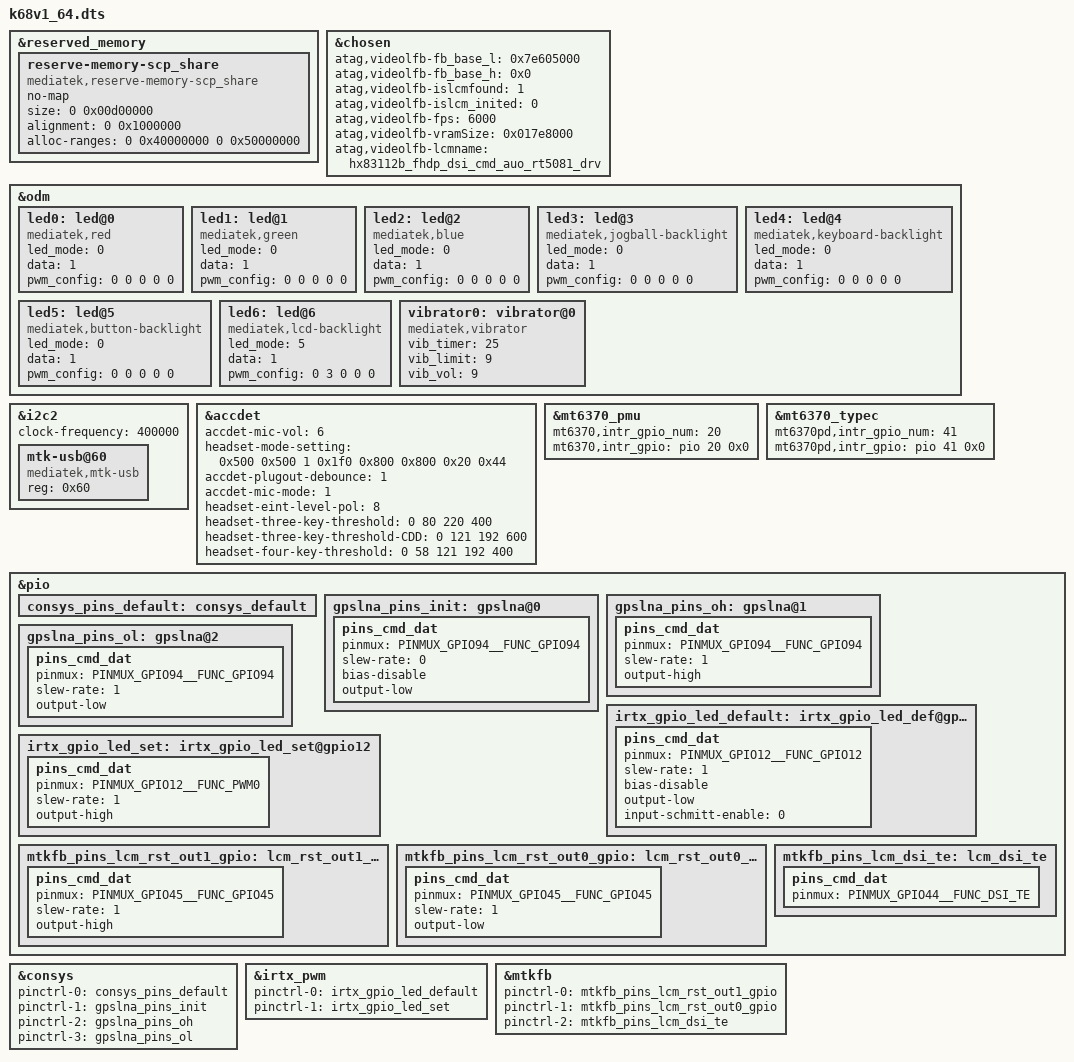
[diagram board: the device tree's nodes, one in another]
/*
 * Copyright (C) 2019 MediaTek Inc.
 *
 * This program is free software; you can redistribute it and/or modify
 * it under the terms of the GNU General Public License version 2 as
 * published by the Free Software Foundation.
 *
 * This program is distributed in the hope that it will be useful,
 * but WITHOUT ANY WARRANTY; without even the implied warranty of
 * MERCHANTABILITY or FITNESS FOR A PARTICULAR PURPOSE.
 * See http://www.gnu.org/licenses/gpl-2.0.html for more details.
 */

/dts-v1/;
/plugin/;
#include <dt-bindings/interrupt-controller/irq.h>
#include <dt-bindings/interrupt-controller/arm-gic.h>
#include <dt-bindings/pinctrl/mt6768-pinfunc.h>

&reserved_memory {
	reserve-memory-scp_share {
		compatible = "mediatek,reserve-memory-scp_share";
		no-map;
		size = <0 0x00d00000>;
		alignment = <0 0x1000000>;
		alloc-ranges = <0 0x40000000 0 0x50000000>;
	};
};

/* chosen */
&chosen {

	atag,videolfb-fb_base_l = <0x7e605000>;
	atag,videolfb-fb_base_h = <0x0>;
	atag,videolfb-islcmfound = <1>;
	atag,videolfb-islcm_inited = <0>;
	atag,videolfb-fps= <6000>;
	atag,videolfb-vramSize= <0x017e8000>;
	atag,videolfb-lcmname=
		"hx83112b_fhdp_dsi_cmd_auo_rt5081_drv";
};

&odm {
	led0:led@0 {
		compatible = "mediatek,red";
		led_mode = <0>;
		data = <1>;
		pwm_config = <0 0 0 0 0>;
	};
	led1:led@1 {
		compatible = "mediatek,green";
		led_mode = <0>;
		data = <1>;
		pwm_config = <0 0 0 0 0>;
	};
	led2:led@2 {
		compatible = "mediatek,blue";
		led_mode = <0>;
		data = <1>;
		pwm_config = <0 0 0 0 0>;
	};
	led3:led@3 {
		compatible = "mediatek,jogball-backlight";
		led_mode = <0>;
		data = <1>;
		pwm_config = <0 0 0 0 0>;
	};
	led4:led@4 {
		compatible = "mediatek,keyboard-backlight";
		led_mode = <0>;
		data = <1>;
		pwm_config = <0 0 0 0 0>;
	};
	led5:led@5 {
		compatible = "mediatek,button-backlight";
		led_mode = <0>;
		data = <1>;
		pwm_config = <0 0 0 0 0>;
	};
	led6:led@6 {
		compatible = "mediatek,lcd-backlight";
		led_mode = <5>;
		data = <1>;
		pwm_config = <0 3 0 0 0>;
	};
	vibrator0:vibrator@0 {
		compatible = "mediatek,vibrator";
		vib_timer = <25>;
		vib_limit = <9>;
		vib_vol= <9>;
	};
};

&i2c2 {
	clock-frequency = <400000>;

	mtk-usb@60 {
		compatible = "mediatek,mtk-usb";
		reg = <0x60>;
		status = "okay";
	};
};

/* accdet start */
&accdet {
	/* accdet micbias voltage: 0x07,2.7v;0x05,2.5v;0x02,1.9v */
	accdet-mic-vol = <6>;
	headset-mode-setting = <0x500 0x500 1 0x1f0 0x800 0x800 0x20 0x44>;
	accdet-plugout-debounce = <1>;
	/*1:ACC mode, 2:low cost without in bias, 6:low cost with in bias*/
	accdet-mic-mode = <1>;
	/* eint_level_trigger: 8,LEVEL_LOW(DEF) ;4,LV_HIGH;others,LV_LOW */
	headset-eint-level-pol = <8>;
	/*0--MD_MAX--UP_MAX--DW_MAX*/
	headset-three-key-threshold = <0 80 220 400>;
	headset-three-key-threshold-CDD = <0 121 192 600>;
	/*0--MD_MAX--VOICE_MAX--UP_MAX--DW_MAX*/
	headset-four-key-threshold = <0 58 121 192 400>;
	status = "okay";
};
/* accdet end */


&mt6370_pmu {
	mt6370,intr_gpio_num = <20>; /* direct defined GPIO num */
	mt6370,intr_gpio = <&pio 20 0x0>;
};
&mt6370_typec {
	mt6370pd,intr_gpio_num = <41>; /* direct defined GPIO num */
	mt6370pd,intr_gpio = <&pio 41 0x0>;
};

/* CONSYS GPIO standardization */
&pio {
	consys_pins_default: consys_default {
	};
	gpslna_pins_init: gpslna@0 {
		pins_cmd_dat {
			pinmux = <PINMUX_GPIO94__FUNC_GPIO94>;
			slew-rate = <0>;
			bias-disable;
			output-low;
		};
	};
	gpslna_pins_oh: gpslna@1 {
		pins_cmd_dat {
			pinmux = <PINMUX_GPIO94__FUNC_GPIO94>;
			slew-rate = <1>;
			output-high;
		};
	};
	gpslna_pins_ol: gpslna@2 {
		pins_cmd_dat {
			pinmux = <PINMUX_GPIO94__FUNC_GPIO94>;
			slew-rate = <1>;
			output-low;
		};
	};
};
&consys {
	pinctrl-names = "default", "gps_lna_state_init",
		"gps_lna_state_oh", "gps_lna_state_ol";
	pinctrl-0 = <&consys_pins_default>;
	pinctrl-1 = <&gpslna_pins_init>;
	pinctrl-2 = <&gpslna_pins_oh>;
	pinctrl-3 = <&gpslna_pins_ol>;
	status = "okay";
};
/* CONSYS end */

/* IRTX GPIO Start */
&irtx_pwm {
	pinctrl-names = "irtx_gpio_led_default", "irtx_gpio_led_set";
	pinctrl-0 = <&irtx_gpio_led_default>;
	pinctrl-1 = <&irtx_gpio_led_set>;
	status = "okay";
};
&pio {
	/* IRTX GPIO Settings -Start */
	/* default: GPIO0, output, high */
	irtx_gpio_led_default:irtx_gpio_led_def@gpio12 {
		pins_cmd_dat {
			pinmux = <PINMUX_GPIO12__FUNC_GPIO12>;
			slew-rate = <1>;
			bias-disable;
			output-low;
			input-schmitt-enable = <0>;
		};
	};

	irtx_gpio_led_set:irtx_gpio_led_set@gpio12 {
		pins_cmd_dat {
			pinmux = <PINMUX_GPIO12__FUNC_PWM0>;
			slew-rate = <1>;
			output-high;
		};
	};
}; /* IRTX GPIO Settings -End */

/* DISPSYS GPIO standardization */
&pio {
	mtkfb_pins_lcm_rst_out1_gpio: lcm_rst_out1_gpio {
		pins_cmd_dat {
			pinmux = <PINMUX_GPIO45__FUNC_GPIO45>;
			slew-rate = <1>;
			output-high;
		};
	};

	mtkfb_pins_lcm_rst_out0_gpio: lcm_rst_out0_gpio {
		pins_cmd_dat {
			pinmux = <PINMUX_GPIO45__FUNC_GPIO45>;
			slew-rate = <1>;
			output-low;
		};
	};

	mtkfb_pins_lcm_dsi_te: lcm_dsi_te {
		pins_cmd_dat {
			pinmux = <PINMUX_GPIO44__FUNC_DSI_TE>;
		};
	};
};

&mtkfb {
	pinctrl-names =
		"lcm_rst_out1_gpio", "lcm_rst_out0_gpio",
		"mode_te_te";
	pinctrl-0 = <&mtkfb_pins_lcm_rst_out1_gpio>;
	pinctrl-1 = <&mtkfb_pins_lcm_rst_out0_gpio>;
	pinctrl-2 = <&mtkfb_pins_lcm_dsi_te>;
	status = "okay";
};

/* DISPSYS GPIO standardization end*/

#include <k68v1_64/cust.dtsi>
#include "mediatek/cust_mt6768_camera.dtsi"
#include "mediatek/cust_mt6768_touch_1080x2160.dtsi"
/*End of this file, DO NOT ADD ANYTHING HERE*/
